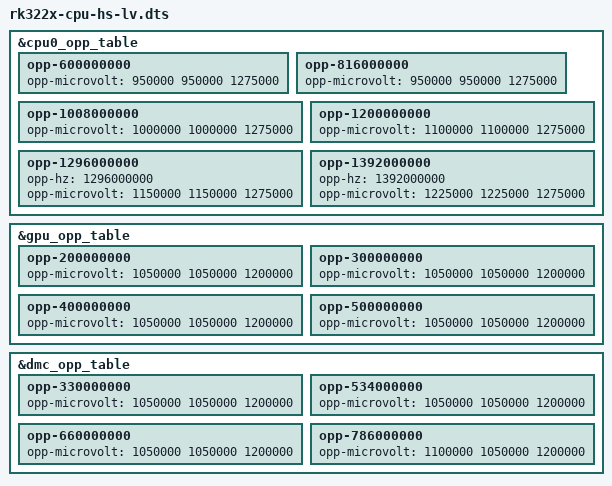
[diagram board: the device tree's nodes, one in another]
/dts-v1/;
/plugin/;

/ {

	fragment@0 {
		target = <&cpu0_opp_table>;
		__overlay__ {
			opp-600000000 {
				opp-microvolt = <950000 950000 1275000>;
			};
			opp-816000000 {
				opp-microvolt = <950000 950000 1275000>;
			};
			opp-1008000000 {
				opp-microvolt = <1000000 1000000 1275000>;
			};
			opp-1200000000 {
				opp-microvolt = <1100000 1100000 1275000>;
			};
			opp-1296000000 {
				opp-hz = /bits/ 64 <1296000000>;
				opp-microvolt = <1150000 1150000 1275000>;
			};
			opp-1392000000 {
				opp-hz = /bits/ 64 <1392000000>;
				opp-microvolt = <1225000 1225000 1275000>;
			};
		};
	};

	fragment@1 {
		target = <&gpu_opp_table>;
		__overlay__ {
			opp-200000000 {
				opp-microvolt = <1050000 1050000 1200000>;
			};
			opp-300000000 {
				opp-microvolt = <1050000 1050000 1200000>;
			};
			opp-400000000 {
				opp-microvolt = <1050000 1050000 1200000>;
			};
			opp-500000000 {
				opp-microvolt = <1050000 1050000 1200000>;
			};
		};
	};

	fragment@2 {
		target = <&dmc_opp_table>;
		__overlay__ {
			opp-330000000 {
				opp-microvolt = <1050000 1050000 1200000>;
			};
			opp-534000000 {
				opp-microvolt = <1050000 1050000 1200000>;
			};
			opp-660000000 {
				opp-microvolt = <1050000 1050000 1200000>;
			};
			opp-786000000 {
				opp-microvolt = <1100000 1050000 1200000>;
			};
		};
	};

};
